# STM32G4xx register map
File version: 1.4
CPU: CM4 r0p1, little endian, MPU, FPU, 4 interrupt priority bits
Registers are 32-bit, read-write, reset 0x0 unless marked. A register's access mark holds for its fields unless they carry their own. Offsets are from the block's base; [hi:lo] are bit positions.

## FDCAN
Base 0x4000A400
Same registers: FDCAN1 0x40006400, FDCAN2 0x40006800, FDCAN3 0x40006C00
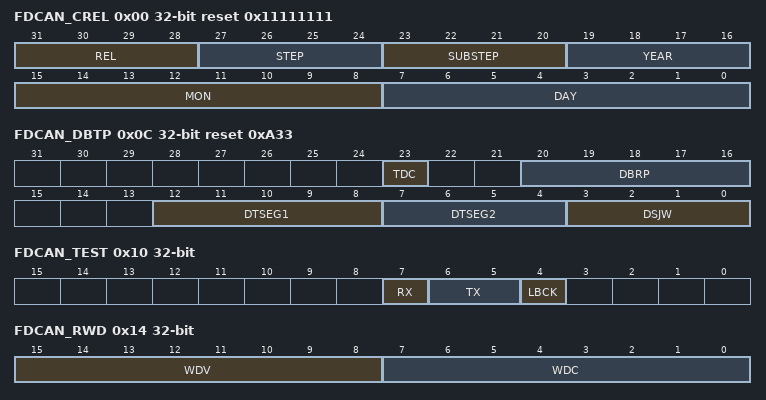
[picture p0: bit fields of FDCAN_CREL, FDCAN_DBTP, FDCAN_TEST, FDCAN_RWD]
0x00 FDCAN_CREL ro reset 0x11111111 — FDCAN Core Release Register
  [31:28] REL, [27:24] STEP, [23:20] SUBSTEP, [19:16] YEAR, [15:8] MON, [7:0] DAY
0x04 FDCAN_ENDN ro reset 0x87654321 — FDCAN Core Release Register
  [31:0] ETV
0x0C FDCAN_DBTP access per field reset 0xA33 — This register is only writable if bits CCCR.CCE and CCCR.INIT are set. The CAN bit time may be programed in the range of 4 to 25 time quanta. The CAN time quantum may be programmed in the range of 1 to 1024 FDCAN clock periods. tq = (DBRP + 1) FDCAN clock period. DTSEG1 is the sum of Prop_Seg and Phase_Seg1. DTSEG2 is Phase_Seg2. Therefore the length of the bit time is (programmed values) [DTSEG1 + DTSEG2 + 3] tq or (functional values) [Sync_Seg + Prop_Seg + Phase_Seg1 + Phase_Seg2] tq. The Information Processing Time (IPT) is zero, meaning the data for the next bit is available at the first clock edge after the sample point.
  [23] TDC ro, [20:16] DBRP rw, [12:8] DTSEG1 wo, [7:4] DTSEG2 rw, [3:0] DSJW rw
0x10 FDCAN_TEST — Write access to the Test Register has to be enabled by setting bit CCCR[TEST] to 1 . All Test Register functions are set to their reset values when bit CCCR[TEST] is reset. Loop Back mode and software control of Tx pin FDCANx_TX are hardware test modes. Programming TX differently from 00 may disturb the message transfer on the CAN bus.
  [7] RX, [6:5] TX, [4] LBCK
0x14 FDCAN_RWD access per field — The RAM Watchdog monitors the READY output of the Message RAM. A Message RAM access starts the Message RAM Watchdog Counter with the value configured by the RWD[WDC] bits. The counter is reloaded with RWD[WDC] bits when the Message RAM signals successful completion by activating its READY output. In case there is no response from the Message RAM until the counter has counted down to 0, the counter stops and interrupt flag IR[WDI] bit is set. The RAM Watchdog Counter is clocked by the fdcan_pclk clock.
  [15:8] WDV ro, [7:0] WDC rw
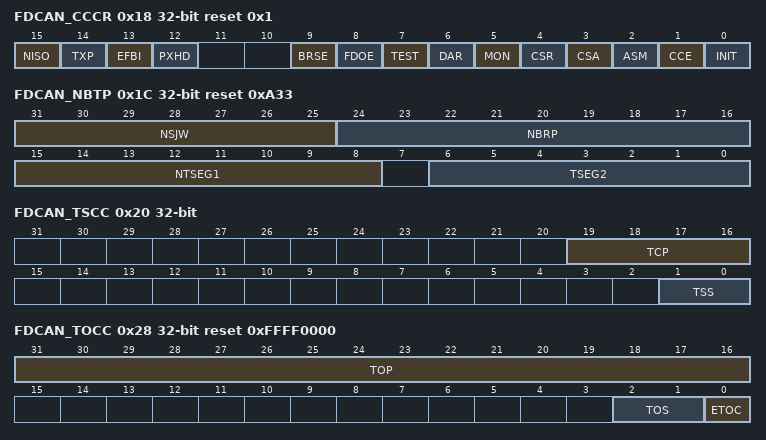
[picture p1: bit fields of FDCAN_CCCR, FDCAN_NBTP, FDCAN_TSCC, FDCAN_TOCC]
0x18 FDCAN_CCCR reset 0x1 — For details about setting and resetting of single bits see Software initialization.
  [15] NISO, [14] TXP, [13] EFBI, [12] PXHD, [9] BRSE, [8] FDOE, [7] TEST, [6] DAR, [5] MON, [4] CSR, [3] CSA, [2] ASM, [1] CCE, [0] INIT
0x1C FDCAN_NBTP reset 0xA33
  [31:25] NSJW, [24:16] NBRP, [15:8] NTSEG1, [6:0] TSEG2
0x20 FDCAN_TSCC — FDCAN Timestamp Counter Configuration Register
  [19:16] TCP, [1:0] TSS
0x24 FDCAN_TSCV ro — FDCAN Timestamp Counter Value Register
  [15:0] TSC
0x28 FDCAN_TOCC access per field reset 0xFFFF0000 — FDCAN Timeout Counter Configuration Register
  [31:16] TOP rw, [2:1] TOS wo, [0] ETOC rw
0x2C FDCAN_TOCV ro reset 0xFFFF — FDCAN Timeout Counter Value Register
  [15:0] TOC
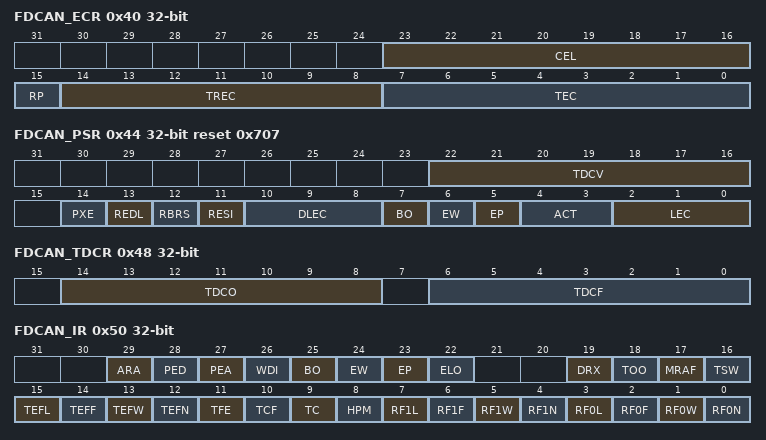
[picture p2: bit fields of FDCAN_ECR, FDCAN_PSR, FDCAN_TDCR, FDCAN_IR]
0x40 FDCAN_ECR ro — FDCAN Error Counter Register
  [23:16] CEL, [15] RP, [14:8] TREC, [7:0] TEC
0x44 FDCAN_PSR access per field reset 0x707 — FDCAN Protocol Status Register
  [22:16] TDCV rw, [14] PXE rw, [13] REDL rw, [12] RBRS rw, [11] RESI rw, [10:8] DLEC wo, [7] BO rw, [6] EW rw, [5] EP rw, [4:3] ACT wo, [2:0] LEC rw
0x48 FDCAN_TDCR ro — FDCAN Transmitter Delay Compensation Register
  [14:8] TDCO, [6:0] TDCF
0x50 FDCAN_IR — The flags are set when one of the listed conditions is detected (edge-sensitive). The flags remain set until the Host clears them. A flag is cleared by writing a 1 to the corresponding bit position. Writing a 0 has no effect. A hard reset will clear the register. The configuration of IE controls whether an interrupt is generated. The configuration of ILS controls on which interrupt line an interrupt is signaled.
  [29] ARA, [28] PED, [27] PEA, [26] WDI, [25] BO, [24] EW, [23] EP, [22] ELO, [19] DRX, [18] TOO, [17] MRAF, [16] TSW, [15] TEFL, [14] TEFF, [13] TEFW, [12] TEFN, [11] TFE, [10] TCF, [9] TC, [8] HPM, [7] RF1L, [6] RF1F, [5] RF1W, [4] RF1N, [3] RF0L, [2] RF0F, [1] RF0W, [0] RF0N
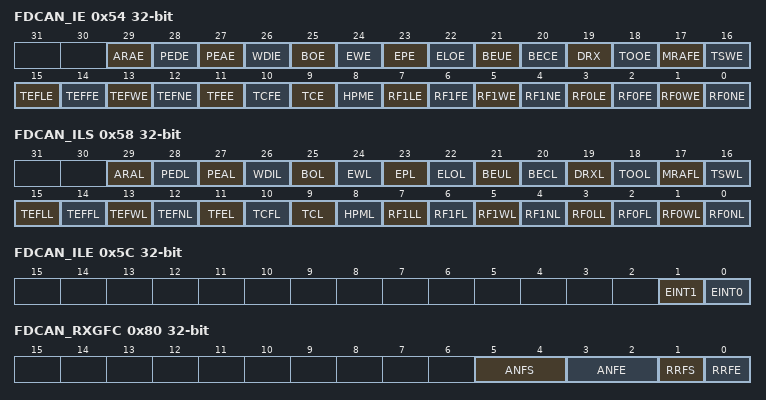
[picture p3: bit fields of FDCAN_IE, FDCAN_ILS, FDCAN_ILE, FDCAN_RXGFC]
0x54 FDCAN_IE — The settings in the Interrupt Enable register determine which status changes in the Interrupt Register will be signaled on an interrupt line.
  [29] ARAE, [28] PEDE, [27] PEAE, [26] WDIE, [25] BOE, [24] EWE, [23] EPE, [22] ELOE, [21] BEUE, [20] BECE, [19] DRX, [18] TOOE, [17] MRAFE, [16] TSWE, [15] TEFLE, [14] TEFFE, [13] TEFWE, [12] TEFNE, [11] TFEE, [10] TCFE, [9] TCE, [8] HPME, [7] RF1LE, [6] RF1FE, [5] RF1WE, [4] RF1NE, [3] RF0LE, [2] RF0FE, [1] RF0WE, [0] RF0NE
0x58 FDCAN_ILS — The Interrupt Line Select register assigns an interrupt generated by a specific interrupt flag from the Interrupt Register to one of the two module interrupt lines. For interrupt generation the respective interrupt line has to be enabled via ILE[EINT0] and ILE[EINT1].
  [29] ARAL, [28] PEDL, [27] PEAL, [26] WDIL, [25] BOL, [24] EWL, [23] EPL, [22] ELOL, [21] BEUL, [20] BECL, [19] DRXL, [18] TOOL, [17] MRAFL, [16] TSWL, [15] TEFLL, [14] TEFFL, [13] TEFWL, [12] TEFNL, [11] TFEL, [10] TCFL, [9] TCL, [8] HPML, [7] RF1LL, [6] RF1FL, [5] RF1WL, [4] RF1NL, [3] RF0LL, [2] RF0FL, [1] RF0WL, [0] RF0NL
0x5C FDCAN_ILE — Each of the two interrupt lines to the CPU can be enabled/disabled separately by programming bits EINT0 and EINT1.
  [1] EINT1, [0] EINT0
0x80 FDCAN_RXGFC access per field — Global settings for Message ID filtering. The Global Filter Configuration controls the filter path for standard and extended messages as described in Figure706: Standard Message ID filter path and Figure707: Extended Message ID filter path.
  [5:4] ANFS wo, [3:2] ANFE wo, [1] RRFS rw, [0] RRFE rw
0x84 FDCAN_XIDAM reset 0x1FFFFFFF — FDCAN Extended ID and Mask Register
  [28:0] EIDM
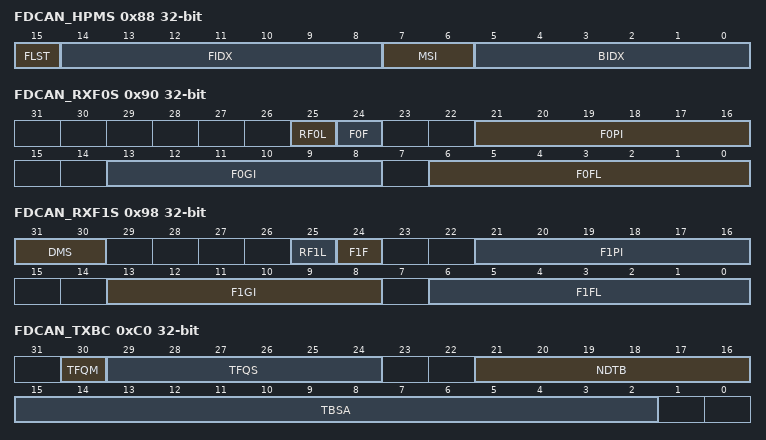
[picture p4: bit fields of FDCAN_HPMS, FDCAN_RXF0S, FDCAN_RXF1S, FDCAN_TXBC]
0x88 FDCAN_HPMS ro — This register is updated every time a Message ID filter element configured to generate a priority event match. This can be used to monitor the status of incoming high priority messages and to enable fast access to these messages.
  [15] FLST, [14:8] FIDX, [7:6] MSI, [5:0] BIDX
0x90 FDCAN_RXF0S — FDCAN Rx FIFO 0 Status Register
  [25] RF0L, [24] F0F, [21:16] F0PI, [13:8] F0GI, [6:0] F0FL
0x94 FDCAN_RXF0A — CAN Rx FIFO 0 Acknowledge Register
  [5:0] F0AI
0x98 FDCAN_RXF1S ro — FDCAN Rx FIFO 1 Status Register
  [31:30] DMS, [25] RF1L, [24] F1F, [21:16] F1PI, [13:8] F1GI, [6:0] F1FL
0x9C FDCAN_RXF1A — FDCAN Rx FIFO 1 Acknowledge Register
  [5:0] F1AI
0xC0 FDCAN_TXBC — FDCAN Tx Buffer Configuration Register
  [30] TFQM, [29:24] TFQS, [21:16] NDTB, [15:2] TBSA
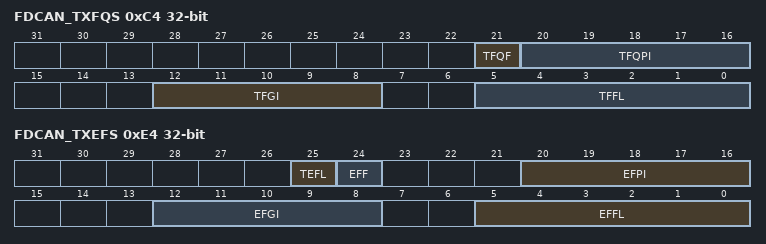
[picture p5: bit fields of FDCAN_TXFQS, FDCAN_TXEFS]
0xC4 FDCAN_TXFQS ro — The Tx FIFO/Queue status is related to the pending Tx requests listed in register TXBRP. Therefore the effect of Add/Cancellation requests may be delayed due to a running Tx scan (TXBRP not yet updated).
  [21] TFQF, [20:16] TFQPI, [12:8] TFGI, [5:0] TFFL
0xC8 FDCAN_TXBRP ro — FDCAN Tx Buffer Request Pending Register
  [31:0] TRP
0xCC FDCAN_TXBAR — FDCAN Tx Buffer Add Request Register
  [31:0] AR
0xD0 FDCAN_TXBCR — FDCAN Tx Buffer Cancellation Request Register
  [31:0] CR
0xD4 FDCAN_TXBTO ro — FDCAN Tx Buffer Transmission Occurred Register
  [31:0] TO
0xD8 FDCAN_TXBCF ro — FDCAN Tx Buffer Cancellation Finished Register
  [31:0] CF
0xDC FDCAN_TXBTIE — FDCAN Tx Buffer Transmission Interrupt Enable Register
  [31:0] TIE
0xE0 FDCAN_TXBCIE — FDCAN Tx Buffer Cancellation Finished Interrupt Enable Register
  [31:0] CFIE
0xE4 FDCAN_TXEFS ro — FDCAN Tx Event FIFO Status Register
  [25] TEFL, [24] EFF, [20:16] EFPI, [12:8] EFGI, [5:0] EFFL
0xE8 FDCAN_TXEFA — FDCAN Tx Event FIFO Acknowledge Register
  [4:0] EFAI
0x100 FDCAN_CKDIV — FDCAN CFG clock divider register
  [3:0] PDIV — input clock divider. the APB clock could be divided prior to be used by the CAN sub
